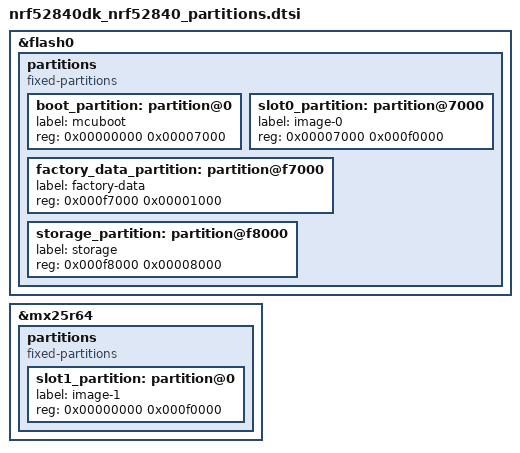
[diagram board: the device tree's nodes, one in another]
/*
 * Copyright (c) 2025 Nordic Semiconductor ASA
 *
 * SPDX-License-Identifier: LicenseRef-Nordic-5-Clause
 */

/delete-node/ &boot_partition;
/delete-node/ &slot0_partition;
/delete-node/ &slot1_partition;
/delete-node/ &storage_partition;

&flash0 {
	partitions {
		compatible = "fixed-partitions";
		#address-cells = <1>;
		#size-cells = <1>;

		boot_partition: partition@0 {
			label = "mcuboot";
			reg = <0x00000000 0x00007000>;
		};

		slot0_partition: partition@7000 {
			label = "image-0";
			reg = <0x00007000 0x000f0000>;
		};

		factory_data_partition: partition@f7000 {
			label = "factory-data";
			reg = <0x000f7000 0x00001000>;
		};

		storage_partition: partition@f8000 {
			label = "storage";
			reg = <0x000f8000 0x00008000>;
		};
	};
};

&mx25r64 {
	partitions {
		compatible = "fixed-partitions";
		#address-cells = <1>;
		#size-cells = <1>;

		slot1_partition: partition@0 {
			label = "image-1";
			reg = <0x00000000 0x000f0000>;
		};
	};
};
